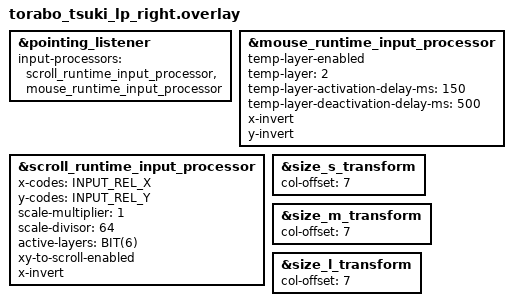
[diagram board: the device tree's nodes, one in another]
#include "torabo_tsuki_lp.dtsi"

&pointing_listener {
    /* Scrollを先に処理すると、Layer 6ではMouse側が変換済みイベントを無視します。 */
    input-processors = <&scroll_runtime_input_processor
                        &mouse_runtime_input_processor>;
};

&mouse_runtime_input_processor {
    /* 右側は従来どおり、150msの待機後に500msのMouseレイヤー2を使用します。 */
    temp-layer-enabled;
    temp-layer = <2>;
    temp-layer-activation-delay-ms = <150>;
    temp-layer-deactivation-delay-ms = <500>;
    x-invert;
    y-invert;
};

&scroll_runtime_input_processor {
    x-codes = <INPUT_REL_X>;
    y-codes = <INPUT_REL_Y>;
    scale-multiplier = <1>;
    scale-divisor = <64>;
    active-layers = <BIT(6)>;
    xy-to-scroll-enabled;
    x-invert;
};

&size_s_transform {
    col-offset = <7>;
};

&size_m_transform {
    col-offset = <7>;
};

&size_l_transform {
    col-offset = <7>;
};
